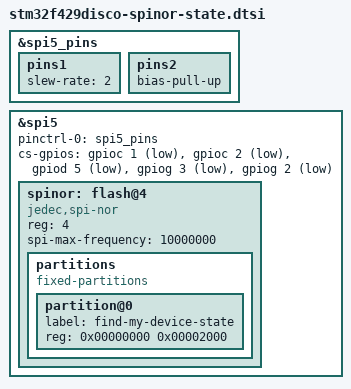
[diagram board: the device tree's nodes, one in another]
/*
 * Filesystem-free W25Q128FV storage for Find My Device. Only the two raw A/B
 * erase sectors are exposed; the standalone SPI-NOR package owns the optional
 * JFFS2 partition covering the rest of the chip.
 * PF7=SCK, PF8=MISO, PF9=MOSI, and PG2=active-low chip select.
 */

&spi5_pins {
	pins1 {
		slew-rate = <2>;
	};

	pins2 {
		bias-pull-up;
	};
};

&spi5 {
	status = "okay";
	pinctrl-names = "default";
	pinctrl-0 = <&spi5_pins>;
	cs-gpios = <&gpioc 1 GPIO_ACTIVE_LOW>,
		     <&gpioc 2 GPIO_ACTIVE_LOW>,
		     <&gpiod 5 GPIO_ACTIVE_LOW>,
		     <&gpiog 3 GPIO_ACTIVE_LOW>,
		     <&gpiog 2 GPIO_ACTIVE_LOW>;

	spinor: flash@4 {
		compatible = "jedec,spi-nor";
		reg = <4>;
		spi-max-frequency = <10000000>;

		partitions {
			compatible = "fixed-partitions";
			#address-cells = <1>;
			#size-cells = <1>;

			partition@0 {
				label = "find-my-device-state";
				reg = <0x00000000 0x00002000>;
			};
		};
	};
};
